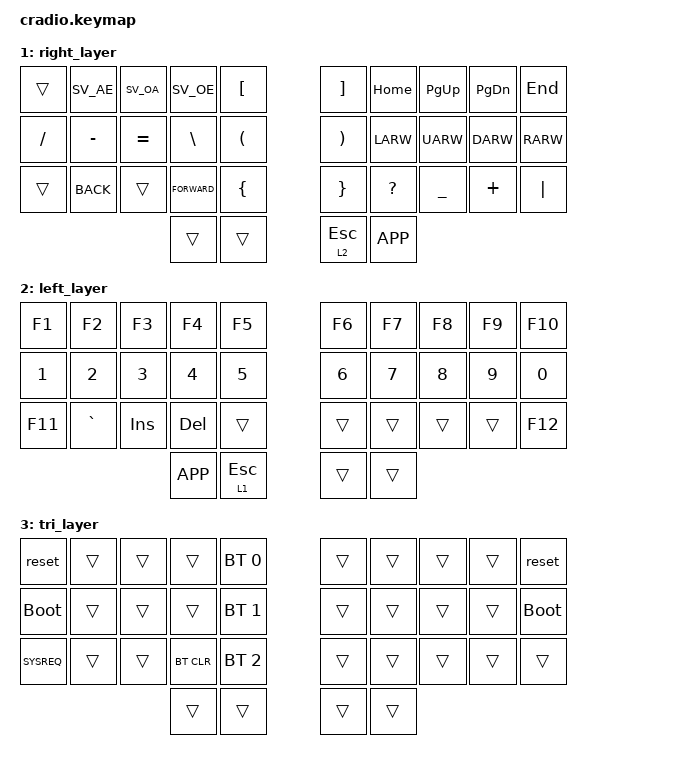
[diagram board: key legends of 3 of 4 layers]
// Copyright (c) 2022 The ZMK Contributors
// SPDX-License-Identifier: MIT

#include <behaviors.dtsi>
#include <dt-bindings/zmk/keys.h>
#include <dt-bindings/zmk/bt.h>

// Home row mods macro
#define HRML(k1,k2,k3,k4) &ht LCTRL k1  &ht LSHFT k2  &ht LALT k3  &ht LGUI k4
#define HRMR(k1,k2,k3,k4) &ht RGUI k1  &ht RALT k2  &ht RSHFT k3  &ht RCTRL k4
#define SCR_UP &kp K_SCROLL_UP
#define SCR_DN &kp K_SCROLL_DOWN
#define FWD K_FORWARD
#define BACK K_BACK
#define SV_OE RA(P)
#define SV_AE RA(Q)
#define SV_OA RA(W)

/ {
    behaviors {
        ht: hold_tap {
            label = "hold_tap";
            compatible = "zmk,behavior-hold-tap";
            #binding-cells = <2>;
            flavor = "tap-preferred";
            tapping-term-ms = <220>;
            quick-tap-ms = <150>;
            global-quick-tap;
            bindings = <&kp>, <&kp>;
        };
    };

    conditional_layers {
        compatible = "zmk,conditional-layers";
        tri_layer {
            if-layers = <1 2>;
            then-layer = <3>;
        };
    };

    keymap {
        compatible = "zmk,keymap";
        default_layer {
            bindings = <
        //╭──────────┬──────────┬──────────┬──────────┬──────────╮   ╭──────────┬──────────┬──────────┬──────────┬──────────╮
        //│  ' "     │  , <     │  . >     │  P       │  Y       │   │  F       │  G       │  C       │  R       │  L       │
            &kp SQT    &kp COMMA  &kp DOT    &kp P      &kp Y          &kp F      &kp G      &kp C      &kp R      &kp L
        //├──────────┼──────────┼──────────┼──────────┼──────────┤   ├──────────┼──────────┼──────────┼──────────┼──────────┤
        //│  A       │  O       │  E       │  U       │  I       │   │  D       │  H       │  T       │  N       │ S        │
            HRML(A,        O,         E,         U)     &kp I          &kp D      HRMR(H,        T,         N,        S)
        //├──────────┼──────────┼──────────┼──────────┼──────────┤   ├──────────┼──────────┼──────────┼──────────┼──────────┤
        //│  ;       │  Q       │  J       │  K       │  X       │   │ B        │  M       │ W        │ V        │ Z        │
            &kp SEMI  &kp Q      &kp J      &kp K      &kp X          &kp B      &kp M      &kp W      &kp V      &kp Z   
        //╰──────────┴──────────┴──────────┼──────────┼──────────┤   ├──────────┼──────────┼──────────┴──────────┴──────────╯
                                            &kp SPACE  &lt 1 BSPC     &lt 2 ENTER &kp TAB
        //                                 ╰──────────┴──────────╯   ╰──────────┴──────────╯
            >;
        };

        right_layer {
            bindings = <
        //╭──────────┬──────────┬──────────┬──────────┬──────────╮   ╭──────────┬──────────┬──────────┬──────────┬──────────╮
        //│          │  Ä       │  Å       │  Ö       │ [        │   │ ]        │ HOME     │ PG_UP    │ PG_DN    │ END      │
            &trans     &kp SV_AE  &kp SV_OA  &kp SV_OE  &kp LBKT       &kp RBKT   &kp HOME   &kp PG_UP  &kp PG_DN  &kp END
        //├──────────┼──────────┼──────────┼──────────┼──────────┤   ├──────────┼──────────┼──────────┼──────────┼──────────┤
        //│ /        │  -       │  +       │  \       │ (        │   │ )        │ LEFT     │ UP       │ DOWN     │ RIGHT    │
            &kp FSLH   &kp MINUS  &kp EQUAL  &kp BSLH   &kp LPAR       &kp RPAR   &kp LARW   &kp UARW   &kp DARW   &kp RARW
        //├──────────┼──────────┼──────────┼──────────┼──────────┤   ├──────────┼──────────┼──────────┼──────────┼──────────┤
        //│          │  <-      │          │  ->      │ {        │   │ }        │ ?        │ _        │ +        │ |        │
            &trans     &kp K_BACK &trans  &kp K_FORWARD &kp LBRC       &kp RBRC   &kp QMARK  &kp UNDER  &kp PLUS   &kp PIPE
        //╰──────────┴──────────┴──────────┼──────────┼──────────┤   ├──────────┼──────────┼──────────┴──────────┴──────────╯
                                             &trans     &trans         &lt 2 ESC  &kp K_APP
        //                                 ╰──────────┴──────────╯   ╰──────────┴──────────╯
            >;
        };

        left_layer {
            bindings = <
        //╭──────────┬──────────┬──────────┬──────────┬──────────╮   ╭──────────┬──────────┬──────────┬──────────┬──────────╮
        //│ F1       │ F2       │ F3       │ F4       │ F5       │   │ F6       │ F7       │ F8       │ F9       │ F10      │
            &kp F1     &kp F2     &kp F3     &kp F4     &kp F5         &kp F6     &kp F7     &kp F8     &kp F9     &kp F10
        //├──────────┼──────────┼──────────┼──────────┼──────────┤   ├──────────┼──────────┼──────────┼──────────┼──────────┤
        //│ 1 !      │ 2 @      │ 3 #      │ 4 $      │ 5 %      │   │ 6 ^      │ 7 &      │ 8 *      │ 9 (      │  0 )     │
            &kp N1     &kp N2     &kp N3     &kp N4     &kp N5         &kp N6     &kp N7     &kp N8     &kp N9      &kp N0
        //├──────────┼──────────┼──────────┼──────────┼──────────┤   ├──────────┼──────────┼──────────┼──────────┼──────────┤
        //│ F11      │  ` ~     │  INSERT  │  DELETE  │          │   │          │          │          │          │ F12      │
            &kp F11    &kp GRAVE  &kp INS    &kp DEL    &trans         &trans     &trans     &trans     &trans     &kp F12
        //╰──────────┴──────────┴──────────┼──────────┼──────────┤   ├──────────┼──────────┼──────────┴──────────┴──────────╯
                                             &kp K_APP  &lt 1 ESC      &trans     &trans
        //                                 ╰──────────┴──────────╯   ╰──────────┴──────────╯
            >;
        };

        tri_layer {
            bindings = <
        //╭──────────┬──────────┬──────────┬──────────┬──────────╮   ╭──────────┬──────────┬──────────┬──────────┬──────────╮
        //│ RESET    │          │          │          │PROFILE 0 │   │          │          │          │          │  RESET   │
            &reset     &trans     &trans     &trans    &bt BT_SEL 0    &trans     &trans     &trans     &trans      &reset
        //├──────────┼──────────┼──────────┼──────────┼──────────┤   ├──────────┼──────────┼──────────┼──────────┼──────────┤
        //│BOOTLOADER│          │          │          │PROFILE 1 │   │          │          │          │          │BOOTLOADER│
          &bootloader  &trans     &trans     &trans    &bt BT_SEL 1    &trans     &trans     &trans     &trans    &bootloader
        //├──────────┼──────────┼──────────┼──────────┼──────────┤   ├──────────┼──────────┼──────────┼──────────┼──────────┤
        //│          │          │          │ CLEAR BT │PROFILE 2 │   │          │          │          │          │          │
           &kp SYSREQ  &trans     &trans    &bt BT_CLR &bt BT_SEL 2    &trans     &trans     &trans     &trans     &trans
        //╰──────────┴──────────┴──────────┼──────────┼──────────┤   ├──────────┼──────────┼──────────┴──────────┴──────────╯
                                             &trans     &trans         &trans     &trans
        //                                 ╰──────────┴──────────╯   ╰──────────┴──────────╯
            >;
        };
    };
};
